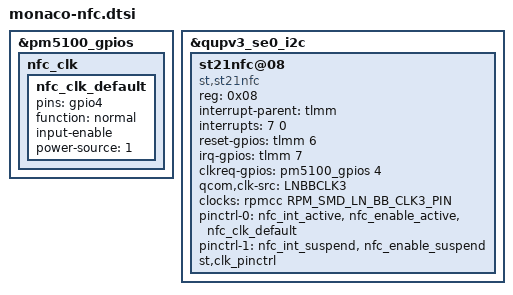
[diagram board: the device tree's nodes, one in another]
&pm5100_gpios {
	nfc_clk {
		nfc_clk_default: nfc_clk_default {
		pins = "gpio4";
		function = "normal";
		input-enable;
		power-source = <1>;
		};
	};
};

&qupv3_se0_i2c {
        status = "ok";
        st21nfc@08 {
                compatible = "st,st21nfc";
                reg = <0x08>;
                interrupt-parent = <&tlmm>;
                interrupts = <7  0>;
		interrupt-names = "st21nfc_irq";
                reset-gpios = <&tlmm 6 0x00>;
                irq-gpios = <&tlmm 7 0x00>;

                clkreq-gpios = <&pm5100_gpios 4 0x00>;
   
		qcom,clk-src = "LNBBCLK3";
                clocks = <&rpmcc RPM_SMD_LN_BB_CLK3_PIN>;
                clock-names = "ref_clk";
		pinctrl-names = "nfc_active";
		pinctrl-0 = <&nfc_int_active &nfc_enable_active &nfc_clk_default>;
		pinctrl-1 = <&nfc_int_suspend &nfc_enable_suspend>;
                st,clk_pinctrl;
                status = "ok";
        };
};

